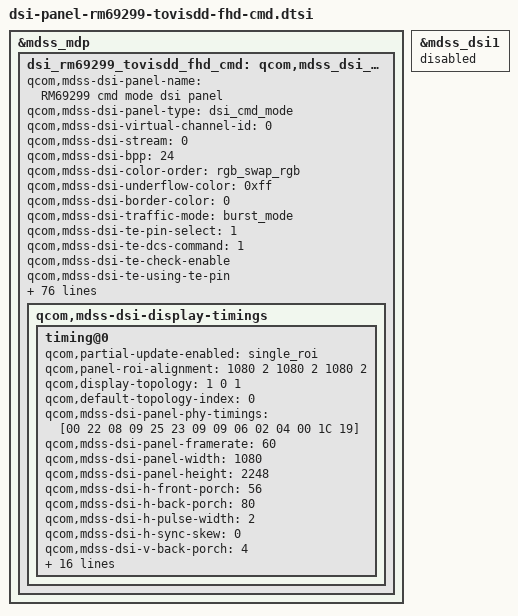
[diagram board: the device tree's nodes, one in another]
/* Copyright (c) 2014, Code Aurora Forum. All rights reserved.
 *
 * This program is free software; you can redistribute it and/or modify
 * it under the terms of the GNU General Public License version 2 and
 * only version 2 as published by the Free Software Foundation.
 *
 * This program is distributed in the hope that it will be useful,
 * but WITHOUT ANY WARRANTY; without even the implied warranty of
 * MERCHANTABILITY or FITNESS FOR A PARTICULAR PURPOSE.  See the
 * GNU General Public License for more details.
 */

&mdss_mdp {
    dsi_rm69299_tovisdd_fhd_cmd: qcom,mdss_dsi_rm69299_tovisdd_fhd_cmd {
		qcom,mdss-dsi-panel-name = "RM69299 cmd mode dsi panel";
		qcom,mdss-dsi-panel-type = "dsi_cmd_mode";
		qcom,mdss-dsi-virtual-channel-id = <0>;
		qcom,mdss-dsi-stream = <0>;
		qcom,mdss-dsi-bpp = <24>;
		qcom,mdss-dsi-color-order = "rgb_swap_rgb";
		qcom,mdss-dsi-underflow-color = <0xff>;
		qcom,mdss-dsi-border-color = <0>;
		qcom,mdss-dsi-traffic-mode = "burst_mode";
		qcom,mdss-dsi-te-pin-select = <1>;
		qcom,mdss-dsi-te-dcs-command = <1>;
		qcom,mdss-dsi-te-check-enable;
		qcom,mdss-dsi-te-using-te-pin;
		qcom,mdss-dsi-lane-map = "lane_map_0123";
		qcom,mdss-dsi-bllp-eof-power-mode;
		qcom,mdss-dsi-bllp-power-mode;
		qcom,mdss-dsi-lane-0-state;
		qcom,mdss-dsi-lane-1-state;
		qcom,mdss-dsi-lane-2-state;
		qcom,mdss-dsi-lane-3-state;
		qcom,mdss-dsi-reset-sequence = <1 10>, <0 2>, <1 10>;
		qcom,mdss-dsi-dma-trigger = "trigger_sw";
		qcom,mdss-dsi-mdp-trigger = "none";
		qcom,mdss-dsi-wr-mem-start = <0x2c>;
		qcom,mdss-dsi-wr-mem-continue = <0x3c>;
		qcom,mdss-dsi-lp11-init;
		qcom,mdss-dsi-tx-eot-append;
		qcom,ulps-enabled;
		qcom,mdss-dsi-panel-peak-brightness = <5643000>;
		qcom,mdss-dsi-panel-blackness-level = <6134>;

		lge,blmap = <
			0
			10 20 29 39 49 59 69 78 88 98 98 99 99 99 100 101 102 103 104 105
			107 108 110 112 114 116 118 120 122 125 128 131 133 136 138 141 144 146 149 152
			154 158 160 163 166 169 172 176 180 184 188 193 196 201 204 209 213 217 222 225
			230 233 238 242 245 249 253 257 261 265 269 272 276 280 285 288 292 296 300 303
			307 311 315 319 323 327 330 334 338 342 346 350 354 358 362 366 371 374 378 383
			386 391 394 399 403 406 411 414 418 422 426 430 434 438 442 447 451 454 459 462
			466 471 474 478 481 486 490 494 498 502 506 510 514 517 521 525 529 533 537 542
			545 549 553 557 561 565 569 574 577 581 585 589 593 596 601 604 609 612 616 620
			624 628 633 637 641 645 650 653 658 661 666 670 674 678 682 687 690 695 699 702
			708 712 716 720 724 728 730 735 738 743 746 750 753 757 761 764 769 772 776 780
			784 788 792 795 799 802 807 811 816 819 824 828 833 837 841 846 849 853 858 862
			865 870 874 879 883 887 890 896 899 904 908 912 916 920 925 930 933 938 941 944
			950 954 958 962 965 970 973 978 983 987 990 994 998 1002 1005 1005 1006 1006 1006 1006
			1006 1006 1006 1007 1007 1007 1007 1008 1008 1009 1009 1009 1010 1011 1012 1012 1013 1014 1014 1015
			1017 1019 1019 1021 1023 1023 1023 1023 1023 1023 1023 1023 1023 1023 1023 1023 1023 1023 1023 1023
			1023 1023 1023 1023 1023 1023 1023 1023 1023 1023 1023 1023 1023 1023 1023 1023 1023 1023 1023 1023
			1023 1023 1023 1023 1023 1023 1023 1023 1023 1023 1023 1023 1023 1023 1023 1023 1023 1023 1023 1023
			1023 1023 1023 1023 1023 1023 1023 1023 1023 1023 1023 1023 1023 1023 1023 1023 1023 1023 1023 1023
			1023 1023 1023 1023 1023
			>;
		lge,blmap-ve = <
			0
			1 1 2 3 5 5 6 7 7 9 9 9 9 10 10 11 13 13 14 17
			18 19 20 23 24 27 30 31 34 37 40 43 44 47 49 53 56 58 61 64
			68 70 73 75 78 82 87 92 98 103 110 115 120 127 132 138 145 150 157 161
			165 168 172 176 182 185 189 193 197 201 205 210 214 220 225 230 234 238 243 247
			252 257 263 269 273 277 282 286 290 295 299 303 307 311 315 320 324 330 333 337
			343 348 352 357 361 366 371 377 381 386 391 398 403 408 415 420 426 432 438 443
			450 455 462 468 474 480 487 493 500 508 515 523 530 536 543 550 557 564 570 577
			585 591 599 607 614 622 629 637 645 653 661 669 677 686 694 701 711 718 728 734
			741 746 752 760 767 775 781 789 796 804 810 818 825 832 839 847 855 861 868 874
			881 887 895 902 908 916 923 931 937 945 952 959 966 972 980 987 995 1003 1009 1015
			1015 1015 1015 1015 1015 1015 1015 1015 1015 1015 1015 1015 1015 1015 1015 1015 1015 1015 1015 1015
			1015 1015 1015 1015 1015 1015 1015 1015 1015 1015 1015 1015 1015 1015 1015 1015 1015 1015 1015 1015
			1015 1015 1015 1015 1015 1015 1015 1015 1015 1015 1015 1015 1015 1015 1015 1015 1015 1015 1015 1015
			1015 1015 1015 1015 1015 1015 1015 1015 1015 1015 1015 1015 1015 1015 1015 1015 1015 1015 1015 1015
			1015 1015 1015 1015 1015 1015 1015 1015 1015 1015 1015 1015 1015 1015 1015 1015 1015 1015 1015 1015
			1015 1015 1015 1015 1015 1015 1015 1015 1015 1015 1015 1015 1015 1015 1015 1015 1015 1015 1015 1015
			1015 1015 1015 1015 1015 1015 1015 1015 1015 1015 1015 1015 1015 1015 1015 1015 1015 1015 1015 1015
			1015 1015 1015 1015 1015 1015 1015 1015 1015 1015 1015 1015 1015 1015 1015 1015 1015 1015 1015 1015
			1015 1015 1015 1015 1015
			>;
		lge,blmap-ex = <
			1
			131 131 131 131 131 131 131 131 131 147 160 175 186 196 208 218 227 234 242 251
			258 264 270 277 284 289 295 300 306 311 317 322 327 332 335 338 350 361 373 384
			393 402 410 418 426 434 442 449 456 462 468 474 480 486 492 498 503 508 513 517
			522 527 532 536 541 545 549 553 557 561 565 569 572 576 580 585 590 595 599 603
			607 612 616 620 624 629 633 637 643 648 654 658 662 667 671 675 679 682 685 688
			691 694 696 699 702 705 708 712 715 718 724 730 736 741 746 752 758 764 774 785
			790 796 801 807 813 819 826 832 838 843 848 854 859 865 865 865 865 865 865 865
			875 883 890 898 905 913 923 931 938 945 953 961 970 978 985 993 999 1006 1012 1012
			1012 1012 1012 1012 1012 1012 1012 1012 1012 1012 1012 1012 1012 1012 1012 1012 1012 1012 1012 1012
			1012 1012 1012 1012 1012 1012 1012 1012 1012 1012 1012 1012 1012 1012 1012 1012 1012 1012 1012 1012
			1012 1012 1012 1012 1012 1012 1012 1012 1012 1012 1012 1012 1012 1012 1012 1012 1012 1012 1012 1012
			1012 1012 1012 1012 1012 1012 1012 1012 1012 1012 1012 1012 1012 1012 1012 1012 1012 1012 1012 1012
			1012 1012 1012 1012 1012 1012 1012 1012 1012 1012 1012 1012 1012 1012 1012
		>;

		qcom,mdss-pan-physical-width-dimension = <68>;
		qcom,mdss-pan-physical-height-dimension = <147>;

		qcom,mdss-dsi-t-clk-post = <0x25>;
		qcom,mdss-dsi-t-clk-pre = <0x28>;

		lge,use-ambient;
		lge,mdss-dsi-nolp-command = [
			15 01 00 00 00 00 02 FE D0
			15 01 00 00 00 00 02 5C C0
			15 01 00 00 00 00 02 FE 00
			05 01 00 00 00 00 01 13
			05 01 00 00 00 00 01 38
		];
		lge,mdss-dsi-nolp-command-state = "dsi_lp_mode";

		lge,mdss-dsi-aod-area-command = [
			15 01 00 00 00 00 02 FE 00
			39 01 00 00 00 00 05 30 00 00 04 37
		];
		lge,mdss-dsi-aod-area-command-state = "dsi_lp_mode";

		lge,mdss-dsi-lp2-command = [
			15 01 00 00 00 00 02 FE 40
			15 01 00 00 00 00 02 4E 01
			15 01 00 00 00 00 02 FE D0
			15 01 00 00 00 00 02 5C D0
			15 01 00 00 00 00 02 FE 00
			05 01 00 00 00 00 01 12
			05 01 00 00 00 00 01 39
		];
		lge,mdss-dsi-lp2-command-state = "dsi_lp_mode";

		lge,use-ddic-register-lock;
		lge,ddic-register-lock = [
			15 01 00 00 10 00 02 FE 00
		];

		lge,use-line-detect;
		lge,detect-vert-line-restore-command = [
			15 01 00 00 00 00 02 FE 40
			15 01 00 00 00 00 02 2D 28
			15 01 00 00 00 00 02 2F 28
			15 01 00 00 00 00 02 30 32
			15 01 00 00 00 00 02 31 32
			15 01 00 00 00 00 02 FE 00
		];
		lge,detect-vert-line-restore-command-state = "dsi_hs_mode";
		lge,detect-black-vert-line-command = [
			15 01 00 00 00 00 02 FE 40
			15 01 00 00 00 00 02 2D 14
			15 01 00 00 00 00 02 2F 14
			15 01 00 00 00 00 02 30 46
			15 01 00 00 00 00 02 31 46
			15 01 00 00 00 00 02 FE 00
		];
		lge,detect-black-vert-line-command-state = "dsi_hs_mode";
		lge,detect-white-vert-line-command = [
			15 01 00 00 00 00 02 FE 40
			15 01 00 00 00 00 02 2D 46
			15 01 00 00 00 00 02 2F 46
			15 01 00 00 00 00 02 30 1E
			15 01 00 00 00 00 02 31 1E
			15 01 00 00 00 00 02 FE 00
		];
		lge,detect-white-vert-line-command-state = "dsi_hs_mode";

		lge,use-bc-dim;
		lge,bc-dimming-work;
		lge,mdss-dsi-bc-default-command = [
			15 00 00 00 00 00 02 FE 70
			15 01 00 00 00 00 02 45 11
			15 01 00 00 00 00 02 FE 00
		];
		lge,mdss-dsi-bc-default-command-state = "dsi_hs_mode";

		lge,use-color-manager;
		lge,color-manager-default-status = <1>;
		lge,mdss-dsi-color-manager-mode-table = <0 1>, <1 1>, <2 1>, <3 1>;
		lge,digital-gamma-absent;
		lge,mdss-dsi-disp-ctrl-command-1 = [
			15 01 00 00 00 00 02 FE 00
			15 01 00 00 00 00 02 53 20
			15 01 00 00 00 00 02 5C 00
			15 01 00 00 00 00 02 FE 80
			15 01 00 00 00 00 02 05 00
			15 01 00 00 00 00 02 FE 12
			15 01 00 00 00 00 02 84 08
			15 01 00 00 00 00 02 FE 00
		];
		lge,mdss-dsi-disp-ctrl-command-1-state = "dsi_hs_mode";
		lge,mdss-dsi-disp-ctrl-command-2 = [
			15 01 00 00 00 00 02 FE 40
			15 01 00 00 00 00 02 79 00
			15 01 00 00 00 00 02 FE 00
		];
		lge,mdss-dsi-disp-ctrl-command-2-state = "dsi_hs_mode";

		lge,color-mode-cmds-dummy = [
			/* CE setting */
			15 00 00 00 00 00 02 FE 00
			15 00 00 00 00 00 02 5A 0B
			/* HUE, SAT enable/disable */
			15 00 00 00 00 00 02 FE 80
			15 00 00 00 00 00 02 00 47
			/* CE gain */
			15 00 00 00 00 00 02 08 00
			15 00 00 00 00 00 02 09 00
			15 00 00 00 00 00 02 0A 0D
			15 00 00 00 00 00 02 0B 00
			15 00 00 00 00 00 02 0C 00
			15 00 00 00 00 00 02 0D 00
			15 00 00 00 00 00 02 0E EF
			15 00 00 00 00 00 02 0F 0F
			/* Skin gain */
			15 00 00 00 00 00 02 1C 77
			15 00 00 00 00 00 02 1D 77
			15 00 00 00 00 00 02 1E 77
			15 00 00 00 00 00 02 1F 77
			15 00 00 00 00 00 02 20 77
			/* Default CM */
			15 00 00 00 00 00 02 FE 10
			15 00 00 00 00 00 02 00 F0
			15 00 00 00 00 00 02 01 26
			15 00 00 00 00 00 02 02 09
			15 00 00 00 00 00 02 03 5C
			15 00 00 00 00 00 02 04 F0
			15 00 00 00 00 00 02 05 80
			15 00 00 00 00 00 02 06 FF
			15 00 00 00 00 00 02 07 C7
			15 00 00 00 00 00 02 08 81
			15 00 00 00 00 00 02 09 19
			15 00 00 00 00 00 02 0A D0
			15 00 00 00 00 00 02 0B 81
			15 00 00 00 00 00 02 0C E3
			15 00 00 00 00 00 02 0D 07
			15 01 00 00 00 00 02 FE 00
		];
		lge,color-mode-cmds-dummy-command = "dsi_hs_mode";

		qcom,mdss-dsi-display-timings {
			timing@0{
				qcom,partial-update-enabled = "single_roi";
				qcom,panel-roi-alignment = <1080 2 1080 2 1080 2>;
				qcom,display-topology = <1 0 1>;
				qcom,default-topology-index = <0>;
				qcom,mdss-dsi-panel-phy-timings = [00 22 08 09 25 23 09 09 06 02 04 00 1C 19];
				qcom,mdss-dsi-panel-framerate = <60>;
				qcom,mdss-dsi-panel-width = <1080>;
				qcom,mdss-dsi-panel-height = <2248>;
				qcom,mdss-dsi-h-front-porch = <56>;
				qcom,mdss-dsi-h-back-porch = <80>;
				qcom,mdss-dsi-h-pulse-width = <2>;
				qcom,mdss-dsi-h-sync-skew = <0>;
				qcom,mdss-dsi-v-back-porch = <4>;
				qcom,mdss-dsi-v-front-porch = <4>;
				qcom,mdss-dsi-v-pulse-width = <2>;
				qcom,mdss-dsi-h-left-border = <0>;
				qcom,mdss-dsi-h-right-border = <0>;
				qcom,mdss-dsi-v-top-border = <0>;
				qcom,mdss-dsi-v-bottom-border = <0>;
				qcom,mdss-mdp-transfer-time-us = <15200>;

				qcom,mdss-dsi-on-command = [
					15 01 00 00 00 00 02 FE 00
					15 01 00 00 00 00 02 C2 08
					05 01 00 00 78 00 01 11
					05 01 00 00 00 00 01 35
				];
				qcom,mdss-dsi-on-command-state = "dsi_lp_mode";

				qcom,mdss-dsi-post-panel-on-command = [
					05 01 00 00 00 00 01 29
				];

				qcom,mdss-dsi-off-command = [
					05 01 00 00 00 00 01 28
					05 01 00 00 96 00 01 10
				];
				qcom,mdss-dsi-off-command-state = "dsi_hs_mode";
				qcom,mdss-dsi-h-sync-pulse = <0>;
			};
		};
	};
};
/*
&spmi_bus {
	qcom,pmi8998@3 {
		labibb: qpnp-labibb-regulator {
			status = "disabled";
		};
	};
};
*/
&mdss_dsi1 {
	status = "disabled";
};
